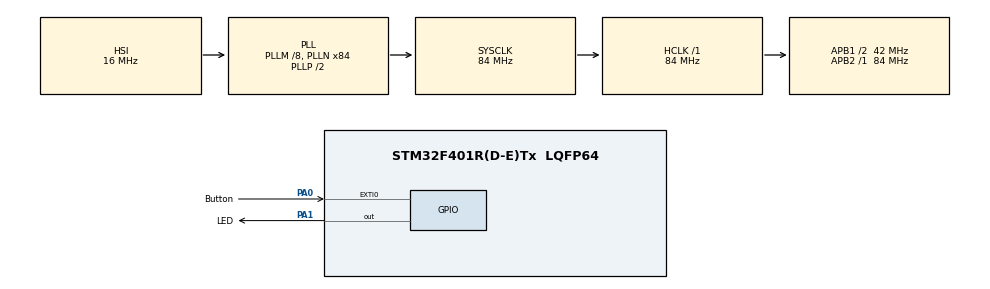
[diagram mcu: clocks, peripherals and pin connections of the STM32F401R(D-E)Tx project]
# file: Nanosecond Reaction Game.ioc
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Mcu.Family=STM32F4
Mcu.Name=STM32F401R(D-E)Tx
Mcu.Package=LQFP64
NVIC.EXTI0_IRQn=true\:0\:0\:false\:false\:true\:true\:true\:true
NVIC.PriorityGroup=NVIC_PRIORITYGROUP_4
PA0-WKUP.GPIO_Label=Button
PA0-WKUP.GPIO_ModeDefaultEXTI=GPIO_MODE_IT_FALLING
PA0-WKUP.GPIO_PuPd=GPIO_PULLUP
PA0-WKUP.Signal=GPXTI0
PA1.GPIO_Label=LED
PA1.GPIO_PuPd=GPIO_PULLUP
PA1.Signal=GPIO_Output
PA13.Mode=Trace_Asynchronous_SW
PA13.Signal=SYS_JTMS-SWDIO
PA14.Mode=Trace_Asynchronous_SW
PA14.Signal=SYS_JTCK-SWCLK
PB3.Mode=Trace_Asynchronous_SW
PB3.Signal=SYS_JTDO-SWO
ProjectManager.HeapSize=0x200
ProjectManager.StackSize=0x400
ProjectManager.TargetToolchain=STM32CubeIDE
RCC.48MHZClocksFreq_Value=42000000
RCC.AHBFreq_Value=84000000
RCC.APB1CLKDivider=RCC_HCLK_DIV2
RCC.APB1Freq_Value=42000000
RCC.APB1TimFreq_Value=84000000
RCC.APB2Freq_Value=84000000
RCC.APB2TimFreq_Value=84000000
RCC.CortexFreq_Value=84000000
RCC.HCLKFreq_Value=84000000
RCC.HSE_VALUE=25000000
RCC.HSI_VALUE=16000000
RCC.LSE_VALUE=32768
RCC.PLLM=8
RCC.PLLN=84
RCC.SYSCLKFreq_VALUE=84000000
RCC.SYSCLKSource=RCC_SYSCLKSOURCE_PLLCLK
RCC.VCOOutputFreq_Value=168000000
board=custom

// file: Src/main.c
/* USER CODE BEGIN Header */
/**
  ******************************************************************************
  * @file           : main.c
  * @brief          : Main program body
  ******************************************************************************
  * @attention
  *
  * Copyright (c) 2026 STMicroelectronics.
  * All rights reserved.
  *
  * This software is licensed under terms that can be found in the LICENSE file
  * in the root directory of this software component.
  * If no LICENSE file comes with this software, it is provided AS-IS.
  *
  ******************************************************************************
  */
/* USER CODE END Header */
#include "main.h"
#include "gpio.h"

/* USER CODE BEGIN Includes */
#include "stdio.h"
/* USER CODE END Includes */

/* USER CODE BEGIN PV */
volatile uint8_t button_pressed = 0;
/* USER CODE END PV */

void SystemClock_Config(void);

/* USER CODE BEGIN 0 */
int _write(int file, char *ptr, int len)
{
	int DataIdx;
	for (DataIdx = 0; DataIdx < len; DataIdx++)
	{
		ITM_SendChar(*ptr++);
	}
	return len;
}
/* USER CODE END 0 */

int main(void)
{

  /* MCU Configuration--------------------------------------------------------*/

  /* Reset of all peripherals, Initializes the Flash interface and the Systick. */
  HAL_Init();

  /* Configure the system clock */
  SystemClock_Config();

  /* Initialize all configured peripherals */
  MX_GPIO_Init();
  /* USER CODE BEGIN 2 */
  CoreDebug->DEMCR |= CoreDebug_DEMCR_TRCENA_Msk;
  DWT->CYCCNT = 0;
  DWT->CTRL |= DWT_CTRL_CYCCNTENA_Msk;
  /* USER CODE END 2 */

  /* Infinite loop */
  while (1)
  {

    /* USER CODE BEGIN 3 */
	  HAL_Delay(5000);
	  HAL_GPIO_WritePin(GPIOA, GPIO_PIN_1, GPIO_PIN_SET);

	  uint32_t start_cycles = DWT->CYCCNT;

	  while (button_pressed == 0);

	  uint32_t end_cycles = DWT->CYCCNT;
	  uint32_t total_cycles = end_cycles - start_cycles;

	  int time_ms = (int) total_cycles / 84000;

	  printf("Reaction Time: %d ms (Cycles: %lu)\n", time_ms, total_cycles);

	  button_pressed = 0;
	  HAL_GPIO_WritePin(GPIOA, GPIO_PIN_1, GPIO_PIN_RESET);
	  HAL_Delay(1000);
  }
  /* USER CODE END 3 */
}

void SystemClock_Config(void)
{
  RCC_OscInitTypeDef RCC_OscInitStruct = {0};
  RCC_ClkInitTypeDef RCC_ClkInitStruct = {0};

  /** Configure the main internal regulator output voltage
  */
  __HAL_RCC_PWR_CLK_ENABLE();
  __HAL_PWR_VOLTAGESCALING_CONFIG(PWR_REGULATOR_VOLTAGE_SCALE2);

  /** Initializes the RCC Oscillators according to the specified parameters
  * in the RCC_OscInitTypeDef structure.
  */
  RCC_OscInitStruct.OscillatorType = RCC_OSCILLATORTYPE_HSI;
  RCC_OscInitStruct.HSIState = RCC_HSI_ON;
  RCC_OscInitStruct.HSICalibrationValue = RCC_HSICALIBRATION_DEFAULT;
  RCC_OscInitStruct.PLL.PLLState = RCC_PLL_ON;
  RCC_OscInitStruct.PLL.PLLSource = RCC_PLLSOURCE_HSI;
  RCC_OscInitStruct.PLL.PLLM = 8;
  RCC_OscInitStruct.PLL.PLLN = 84;
  RCC_OscInitStruct.PLL.PLLP = RCC_PLLP_DIV2;
  RCC_OscInitStruct.PLL.PLLQ = 4;
  if (HAL_RCC_OscConfig(&RCC_OscInitStruct) != HAL_OK)
  {
    Error_Handler();
  }

  /** Initializes the CPU, AHB and APB buses clocks
  */
  RCC_ClkInitStruct.ClockType = RCC_CLOCKTYPE_HCLK|RCC_CLOCKTYPE_SYSCLK
                              |RCC_CLOCKTYPE_PCLK1|RCC_CLOCKTYPE_PCLK2;
  RCC_ClkInitStruct.SYSCLKSource = RCC_SYSCLKSOURCE_PLLCLK;
  RCC_ClkInitStruct.AHBCLKDivider = RCC_SYSCLK_DIV1;
  RCC_ClkInitStruct.APB1CLKDivider = RCC_HCLK_DIV2;
  RCC_ClkInitStruct.APB2CLKDivider = RCC_HCLK_DIV1;

  if (HAL_RCC_ClockConfig(&RCC_ClkInitStruct, FLASH_LATENCY_2) != HAL_OK)
  {
    Error_Handler();
  }
}

/* USER CODE BEGIN 4 */
void HAL_GPIO_EXTI_Callback(uint16_t GPIO_Pin)
{
	if (GPIO_Pin == GPIO_PIN_0)
	{
		button_pressed = 1;
	}
}
/* USER CODE END 4 */

void Error_Handler(void)
{
  __disable_irq();
  while (1)
  {
  }
}
